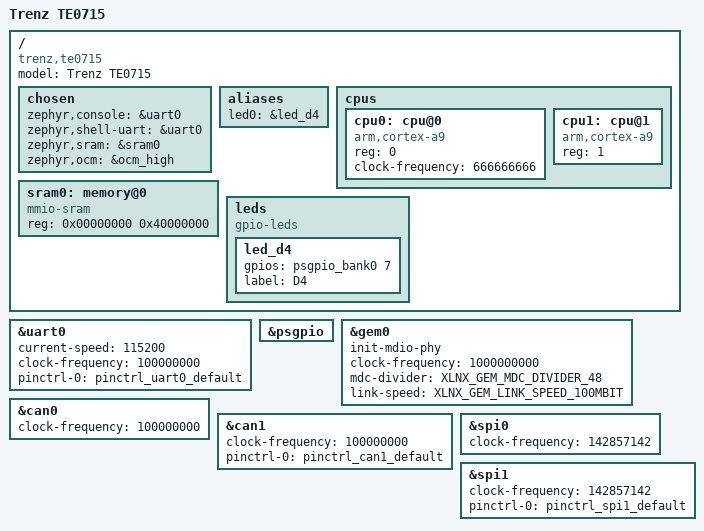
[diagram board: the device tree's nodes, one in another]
/dts-v1/;
#include <xilinx/zynq7000.dtsi>
#include <zephyr/dt-bindings/gpio/gpio.h>

#include "te0715-pinctrl.dtsi"
#include "zynq7000-spi.dtsi"

/ {
    model = "Trenz TE0715";
    compatible = "trenz,te0715", "xlnx,zynq-7000";

    #address-cells = <1>;
    #size-cells = <1>;

    chosen {
        zephyr,console = &uart0;
        zephyr,shell-uart = &uart0;
        zephyr,sram = &sram0;
        zephyr,ocm = &ocm_high;
    };

    aliases {
        led0 = &led_d4;
    };

    cpus {
        #address-cells = <1>;
        #size-cells = <0>;

        cpu0: cpu@0 {
            device_type = "cpu";
            compatible = "arm,cortex-a9";
            reg = <0>;
            /* TE0715 standard speed is 667 MHz */
            clock-frequency = <666666666>;
        };

        cpu1: cpu@1 {
            device_type = "cpu";
            compatible = "arm,cortex-a9";
            reg = <1>;
        };
    };

    /* 1 GB DDR3 SDRAM */    
    sram0: memory@0 {
        device_type = "memory";
        compatible = "mmio-sram";
        reg = <0x00000000 0x40000000>;
    };

    leds {
        compatible = "gpio-leds";

        /* Green user LED D4 on the module. MIO7 is muxed to GPIO by ps7_init. */
        led_d4: led_d4 {
            gpios = <&psgpio_bank0 7 GPIO_ACTIVE_HIGH>;
            label = "D4";
        };
    };
};

&uart0 {
    status = "okay";
    current-speed = <115200>;
    clock-frequency = <100000000>;
    pinctrl-0 = <&pinctrl_uart0_default>;
    pinctrl-names = "default";
};

&psgpio {
    status = "okay";
};

/*
 * Ethernet: PS GEM0 on MIO16-27 (RGMII) and MDIO on MIO52/53, muxed by the FSBL or
 * ps7_init.tcl; the GEM driver applies no pin configuration. The driver derives the
 * GEM reference clock from the IO PLL (1000 MHz). The module's Marvell 88E151x PHY
 * answers at MDIO address 0 (TC-23). The driver cannot pin address 0 (0 means
 * auto-detection), but its scan starts at 0, so it claims this PHY: the
 * mdio-phy-address of zynq7000.dtsi stays. 100 Mbit/s full duplex is CubeSpec's baseline.
 * The driver takes the MAC address only from local-mac-address, so an application
 * that enables networking must set it.
 */
&gem0 {
    status = "okay";
    /* The driver manages the PHY: reset, advertisement, link polling */
    init-mdio-phy;
    clock-frequency = <1000000000>;
    /* MDC = CPU_1x (111 MHz) / 48 = 2.31 MHz, within the 2.5 MHz of IEEE 802.3 clause 22 */
    mdc-divider = <XLNX_GEM_MDC_DIVIDER_48>;
    link-speed = <XLNX_GEM_LINK_SPEED_100MBIT>;
};

/* CAN_REF_CLK is set up by board.c */
&can0 {
    clock-frequency = <100000000>;
};

&can1 {
    clock-frequency = <100000000>;
    pinctrl-0 = <&pinctrl_can1_default>;
    pinctrl-names = "default";
};

/*
 * SPI_REF_CLK is set up by board.c (IO PLL / 7). The SPI driver does not apply
 * pinctrl; board.c applies SPI1's pin state when the controller is enabled.
 */
&spi0 {
    clock-frequency = <142857142>;
};

&spi1 {
    clock-frequency = <142857142>;
    pinctrl-0 = <&pinctrl_spi1_default>;
    pinctrl-names = "default";
};
